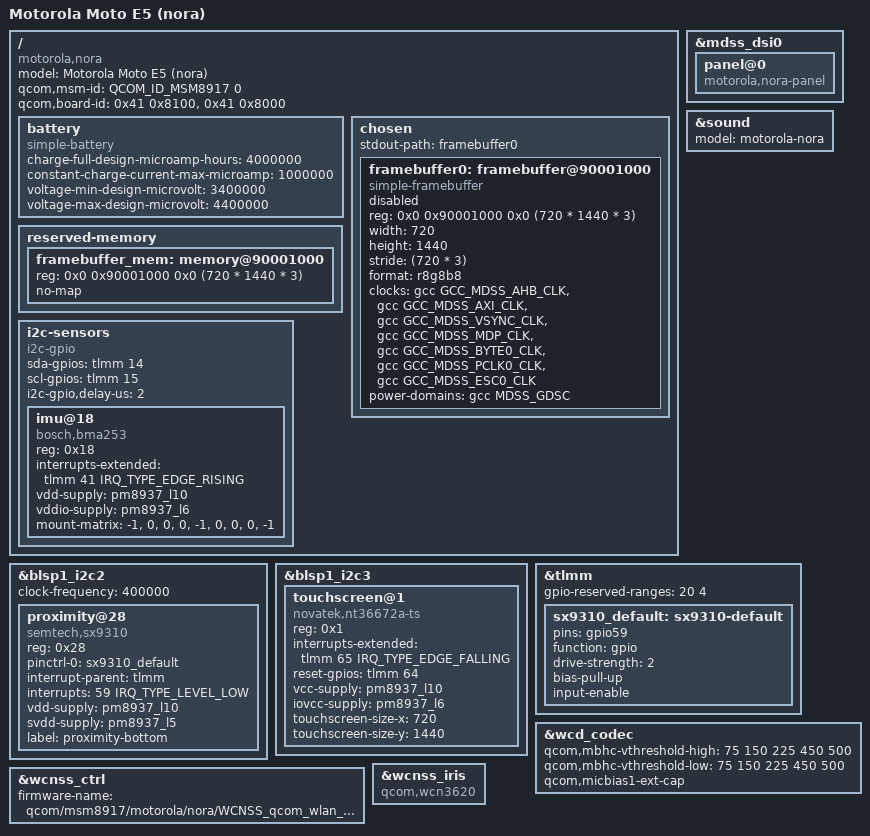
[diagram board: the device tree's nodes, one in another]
// SPDX-License-Identifier: BSD-3-Clause
/*
 * Copyright (c) 2025 Val Packett
 */

/dts-v1/;

#include "msm8917.dtsi"
#include "msm8937-msm8917-motorola-common.dtsi"

/ {
	model = "Motorola Moto E5 (nora)";
	compatible = "motorola,nora", "qcom,msm8917";
	qcom,msm-id = <QCOM_ID_MSM8917 0>;
	qcom,board-id = <0x41 0x8100>,
			<0x41 0x8000>;

	battery: battery {
		compatible = "simple-battery";

		charge-full-design-microamp-hours = <4000000>;
		constant-charge-current-max-microamp = <1000000>;
		voltage-min-design-microvolt = <3400000>;
		voltage-max-design-microvolt = <4400000>;
	};

	chosen {
		#address-cells = <2>;
		#size-cells = <2>;
		ranges;

		stdout-path = "framebuffer0";

		framebuffer0: framebuffer@90001000 {
			compatible = "simple-framebuffer";
			reg = <0x0 0x90001000 0x0 (720 * 1440 * 3)>;
			width = <720>;
			height = <1440>;
			stride = <(720 * 3)>;
			format = "r8g8b8";

			clocks = <&gcc GCC_MDSS_AHB_CLK>,
				 <&gcc GCC_MDSS_AXI_CLK>,
				 <&gcc GCC_MDSS_VSYNC_CLK>,
				 <&gcc GCC_MDSS_MDP_CLK>,
				 <&gcc GCC_MDSS_BYTE0_CLK>,
				 <&gcc GCC_MDSS_PCLK0_CLK>,
				 <&gcc GCC_MDSS_ESC0_CLK>;
			power-domains = <&gcc MDSS_GDSC>;

			status = "disabled";
		};
	};

	reserved-memory {
		framebuffer_mem: memory@90001000 {
			reg = <0x0 0x90001000 0x0 (720 * 1440 * 3)>;
			no-map;
		};
	};

	/*
	 * We bitbang on &i2c_4 because BLSP is protected by TZ as sensors are
	 * normally proxied via ADSP firmware. GPIOs aren't protected.
	 */
	i2c-sensors {
		compatible = "i2c-gpio";
		sda-gpios = <&tlmm 14 (GPIO_ACTIVE_HIGH|GPIO_OPEN_DRAIN)>;
		scl-gpios = <&tlmm 15 (GPIO_ACTIVE_HIGH|GPIO_OPEN_DRAIN)>;
		i2c-gpio,delay-us = <2>; /* ~100 kHz */
		#address-cells = <1>;
		#size-cells = <0>;

		imu@18 {
			compatible = "bosch,bma253";
			reg = <0x18>;

			interrupts-extended = <&tlmm 41 IRQ_TYPE_EDGE_RISING>;

			vdd-supply = <&pm8937_l10>;
			vddio-supply = <&pm8937_l6>;

			mount-matrix = "-1", "0", "0",
					"0", "-1", "0",
					"0", "0", "-1";
		};
	};
};

&blsp1_i2c2 {
	clock-frequency = <400000>;

	status = "okay";

	proximity@28 {
		compatible = "semtech,sx9310";
		reg = <0x28>;
		#io-channel-cells = <1>;
		pinctrl-0 = <&sx9310_default>;
		pinctrl-names = "default";

		interrupt-parent = <&tlmm>;
		interrupts = <59 IRQ_TYPE_LEVEL_LOW>;

		vdd-supply = <&pm8937_l10>;
		svdd-supply = <&pm8937_l5>;

		label = "proximity-bottom";
	};
};

&blsp1_i2c3 {
	status = "okay";

	touchscreen@1 {
		compatible = "novatek,nt36672a-ts";
		reg = <0x1>;
		interrupts-extended = <&tlmm 65 IRQ_TYPE_EDGE_FALLING>;
		reset-gpios = <&tlmm 64 GPIO_ACTIVE_HIGH>;
		vcc-supply = <&pm8937_l10>;
		iovcc-supply = <&pm8937_l6>;
		touchscreen-size-x = <720>;
		touchscreen-size-y = <1440>;
	};

	/* ILI9881 @ 0x41 */
};

&mdss_dsi0 {
	panel@0 {
		compatible = "motorola,nora-panel";
	};
};

&sound {
	model = "motorola-nora";
};

&tlmm {
	gpio-reserved-ranges = <20 4>;

	sx9310_default: sx9310-default {
		pins = "gpio59";
		function = "gpio";
		drive-strength = <2>;
		bias-pull-up;
		input-enable;
	};
};

&wcd_codec {
	qcom,mbhc-vthreshold-high = <75 150 225 450 500>;
	qcom,mbhc-vthreshold-low = <75 150 225 450 500>;
	qcom,micbias1-ext-cap;
};

&wcnss_ctrl {
	firmware-name = "qcom/msm8917/motorola/nora/WCNSS_qcom_wlan_nv.bin";
};

&wcnss_iris {
	compatible = "qcom,wcn3620";
};
